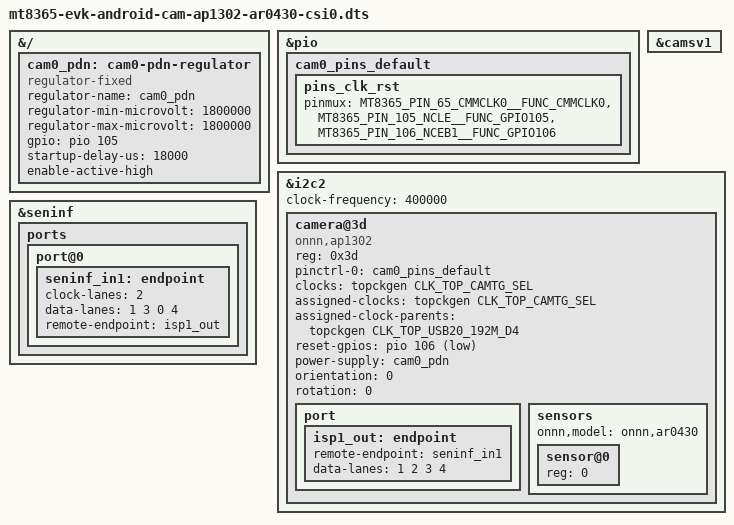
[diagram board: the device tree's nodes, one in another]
// SPDX-License-Identifier: GPL-2.0
/*
 * Copyright (c) 2025 BayLibre, SAS.
 * Author: Vitor Sato Eschholz <vsatoes@baylibre.com>
 */

/dts-v1/;
/plugin/;

#include <dt-bindings/clock/mt8365-clk.h>
#include <dt-bindings/gpio/gpio.h>
#include <dt-bindings/input/input.h>
#include <dt-bindings/pinctrl/mt8365-pinfunc.h>

&{/} {
	cam0_pdn: cam0-pdn-regulator {
		compatible = "regulator-fixed";
		regulator-name = "cam0_pdn";
		regulator-min-microvolt = <1800000>;
		regulator-max-microvolt = <1800000>;
		gpio = <&pio 105 0>;
		startup-delay-us = <18000>;
		enable-active-high;
	};
};

&pio {
	cam0_pins_default: cam0_pins_default {
		pins_clk_rst {
			pinmux = <MT8365_PIN_65_CMMCLK0__FUNC_CMMCLK0>,
				<MT8365_PIN_105_NCLE__FUNC_GPIO105>,
				<MT8365_PIN_106_NCEB1__FUNC_GPIO106>;
		};
	};
};

&camsv1 {
	status = "okay";
};

&i2c2 {
	clock-frequency = <400000>;

	camera@3d {
		compatible = "onnn,ap1302";
		reg = <0x3d>;

		pinctrl-names = "default";
		pinctrl-0 = <&cam0_pins_default>;

		clocks = <&topckgen CLK_TOP_CAMTG_SEL>;
		assigned-clocks = <&topckgen CLK_TOP_CAMTG_SEL>;
		assigned-clock-parents = <&topckgen CLK_TOP_USB20_192M_D4>;

		reset-gpios = <&pio 106 GPIO_ACTIVE_LOW>;

		power-supply = <&cam0_pdn>;

		orientation = <0>;
		rotation = <0>;

		port {
			isp1_out: endpoint {
				remote-endpoint = <&seninf_in1>;
				data-lanes = <1 2 3 4>;
			};
		};

		sensors {
			#address-cells = <1>;
			#size-cells = <0>;

			onnn,model = "onnn,ar0430";

			sensor@0 {
				reg = <0>;
			};
		};
	};
};

&seninf {
	status = "okay";

	ports {
		port@0 {
			seninf_in1: endpoint {
				clock-lanes = <2>;
				data-lanes = <1 3 0 4>;
				remote-endpoint = <&isp1_out>;
			};

		};
	};
};
